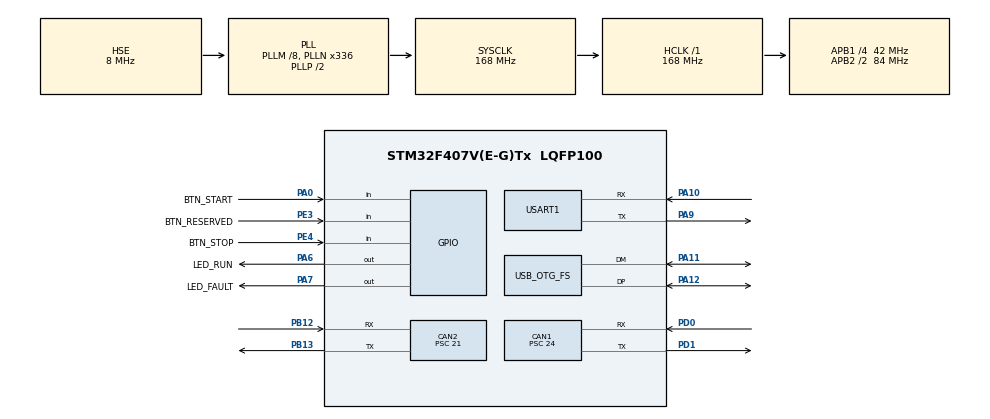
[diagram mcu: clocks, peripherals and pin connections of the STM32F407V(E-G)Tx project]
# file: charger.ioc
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CAN1.ABOM=ENABLE
CAN1.BS1=CAN_BS1_11TQ
CAN1.BS2=CAN_BS2_2TQ
CAN1.CalculateBaudRate=125000
CAN1.CalculateTimeBit=8000
CAN1.CalculateTimeQuantum=571.4285714285714
CAN1.NART=ENABLE
CAN1.Prescaler=24
CAN2.BS1=CAN_BS1_13TQ
CAN2.BS2=CAN_BS2_2TQ
CAN2.CalculateBaudRate=125000
CAN2.CalculateTimeBit=8000
CAN2.CalculateTimeQuantum=500.0
CAN2.Prescaler=21
Mcu.Family=STM32F4
Mcu.Name=STM32F407V(E-G)Tx
Mcu.Package=LQFP100
NVIC.CAN1_RX0_IRQn=true\:0\:0\:false\:false\:true\:true\:true\:true
NVIC.CAN1_SCE_IRQn=true\:0\:0\:false\:false\:true\:true\:true\:true
NVIC.CAN2_RX0_IRQn=true\:0\:0\:false\:false\:true\:true\:true\:true
NVIC.OTG_FS_IRQn=true\:0\:0\:false\:false\:true\:false\:true\:true
NVIC.PriorityGroup=NVIC_PRIORITYGROUP_4
NVIC.USART1_IRQn=true\:0\:0\:false\:false\:true\:true\:true\:true
PA0-WKUP.GPIO_Label=BTN_START
PA0-WKUP.GPIO_PuPd=GPIO_PULLDOWN
PA0-WKUP.Signal=GPIO_Input
PA10.Mode=Asynchronous
PA10.Signal=USART1_RX
PA11.Mode=Device_Only
PA11.Signal=USB_OTG_FS_DM
PA12.Mode=Device_Only
PA12.Signal=USB_OTG_FS_DP
PA13.Mode=Serial_Wire
PA13.Signal=SYS_JTMS-SWDIO
PA14.Mode=Serial_Wire
PA14.Signal=SYS_JTCK-SWCLK
PA6.GPIO_Label=LED_RUN
PA6.Signal=GPIO_Output
PA7.GPIO_Label=LED_FAULT
PA7.Signal=GPIO_Output
PA9.Mode=Asynchronous
PA9.Signal=USART1_TX
PB12.Mode=CAN_Activate
PB12.Signal=CAN2_RX
PB13.Mode=CAN_Activate
PB13.Signal=CAN2_TX
PC14-OSC32_IN.Mode=LSE-External-Oscillator
PC14-OSC32_IN.Signal=RCC_OSC32_IN
PC15-OSC32_OUT.Mode=LSE-External-Oscillator
PC15-OSC32_OUT.Signal=RCC_OSC32_OUT
PD0.Mode=CAN_Activate
PD0.Signal=CAN1_RX
PD1.Mode=CAN_Activate
PD1.Signal=CAN1_TX
PE3.GPIO_Label=BTN_RESERVED
PE3.GPIO_PuPd=GPIO_PULLUP
PE3.Signal=GPIO_Input
PE4.GPIO_Label=BTN_STOP
PE4.GPIO_PuPd=GPIO_PULLUP
PE4.Signal=GPIO_Input
PH0-OSC_IN.Mode=HSE-External-Oscillator
PH0-OSC_IN.Signal=RCC_OSC_IN
PH1-OSC_OUT.Mode=HSE-External-Oscillator
PH1-OSC_OUT.Signal=RCC_OSC_OUT
ProjectManager.HeapSize=0x200
ProjectManager.StackSize=0x1000
ProjectManager.TargetToolchain=CMake
RCC.48MHZClocksFreq_Value=48000000
RCC.AHBFreq_Value=168000000
RCC.APB1CLKDivider=RCC_HCLK_DIV4
RCC.APB1Freq_Value=42000000
RCC.APB1TimFreq_Value=84000000
RCC.APB2CLKDivider=RCC_HCLK_DIV2
RCC.APB2Freq_Value=84000000
RCC.APB2TimFreq_Value=168000000
RCC.CortexFreq_Value=168000000
RCC.HCLKFreq_Value=168000000
RCC.HSE_VALUE=8000000
RCC.HSI_VALUE=16000000
RCC.PLLM=8
RCC.PLLN=336
RCC.PLLQ=7
RCC.SYSCLKFreq_VALUE=168000000
RCC.SYSCLKSource=RCC_SYSCLKSOURCE_PLLCLK
RCC.VCOOutputFreq_Value=336000000
USART1.VirtualMode=VM_ASYNC
USB_DEVICE.CLASS_NAME_FS=CDC
USB_DEVICE.VirtualMode-CDC_FS=Cdc
USB_DEVICE.VirtualModeFS=Cdc_FS
USB_OTG_FS.VirtualMode=Device_Only
VP_USB_DEVICE_VS_USB_DEVICE_CDC_FS.Mode=CDC_FS
board=custom

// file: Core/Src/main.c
/* USER CODE BEGIN Header */
/**
  ******************************************************************************
  * @file           : main.c
  * @brief          : Main program body
  ******************************************************************************
  * @attention
  *
  * Copyright (c) 2026 STMicroelectronics.
  * All rights reserved.
  *
  * This software is licensed under terms that can be found in the LICENSE file
  * in the root directory of this software component.
  * If no LICENSE file comes with this software, it is provided AS-IS.
  *
  ******************************************************************************
  */
/* USER CODE END Header */
#include "main.h"
#include "can.h"
#include "usart.h"
#include "usb_device.h"
#include "gpio.h"

/* USER CODE BEGIN Includes */
#include "app_charger.h"
/* USER CODE END Includes */

void SystemClock_Config(void);

int main(void)
{

  /* MCU Configuration--------------------------------------------------------*/

  /* Reset of all peripherals, Initializes the Flash interface and the Systick. */
  HAL_Init();

  /* Configure the system clock */
  SystemClock_Config();

  /* Initialize all configured peripherals */
  MX_GPIO_Init();
  MX_CAN1_Init();
  MX_USART1_UART_Init();
  MX_USB_DEVICE_Init();
  MX_CAN2_Init();
  /* USER CODE BEGIN 2 */
  App_Init();
  /* USER CODE END 2 */

  /* Infinite loop */
  while (1)
  {

    /* USER CODE BEGIN 3 */
    App_Loop();
  }
  /* USER CODE END 3 */
}

void SystemClock_Config(void)
{
  RCC_OscInitTypeDef RCC_OscInitStruct = {0};
  RCC_ClkInitTypeDef RCC_ClkInitStruct = {0};

  /** Configure the main internal regulator output voltage
  */
  __HAL_RCC_PWR_CLK_ENABLE();
  __HAL_PWR_VOLTAGESCALING_CONFIG(PWR_REGULATOR_VOLTAGE_SCALE1);

  /** Initializes the RCC Oscillators according to the specified parameters
  * in the RCC_OscInitTypeDef structure.
  */
  RCC_OscInitStruct.OscillatorType = RCC_OSCILLATORTYPE_HSE;
  RCC_OscInitStruct.HSEState = RCC_HSE_ON;
  RCC_OscInitStruct.PLL.PLLState = RCC_PLL_ON;
  RCC_OscInitStruct.PLL.PLLSource = RCC_PLLSOURCE_HSE;
  RCC_OscInitStruct.PLL.PLLM = 8;
  RCC_OscInitStruct.PLL.PLLN = 336;
  RCC_OscInitStruct.PLL.PLLP = RCC_PLLP_DIV2;
  RCC_OscInitStruct.PLL.PLLQ = 7;
  if (HAL_RCC_OscConfig(&RCC_OscInitStruct) != HAL_OK)
  {
    Error_Handler();
  }

  /** Initializes the CPU, AHB and APB buses clocks
  */
  RCC_ClkInitStruct.ClockType = RCC_CLOCKTYPE_HCLK|RCC_CLOCKTYPE_SYSCLK
                              |RCC_CLOCKTYPE_PCLK1|RCC_CLOCKTYPE_PCLK2;
  RCC_ClkInitStruct.SYSCLKSource = RCC_SYSCLKSOURCE_PLLCLK;
  RCC_ClkInitStruct.AHBCLKDivider = RCC_SYSCLK_DIV1;
  RCC_ClkInitStruct.APB1CLKDivider = RCC_HCLK_DIV4;
  RCC_ClkInitStruct.APB2CLKDivider = RCC_HCLK_DIV2;

  if (HAL_RCC_ClockConfig(&RCC_ClkInitStruct, FLASH_LATENCY_5) != HAL_OK)
  {
    Error_Handler();
  }
}

void Error_Handler(void)
{
  __disable_irq();
  while (1)
  {
  }
}
